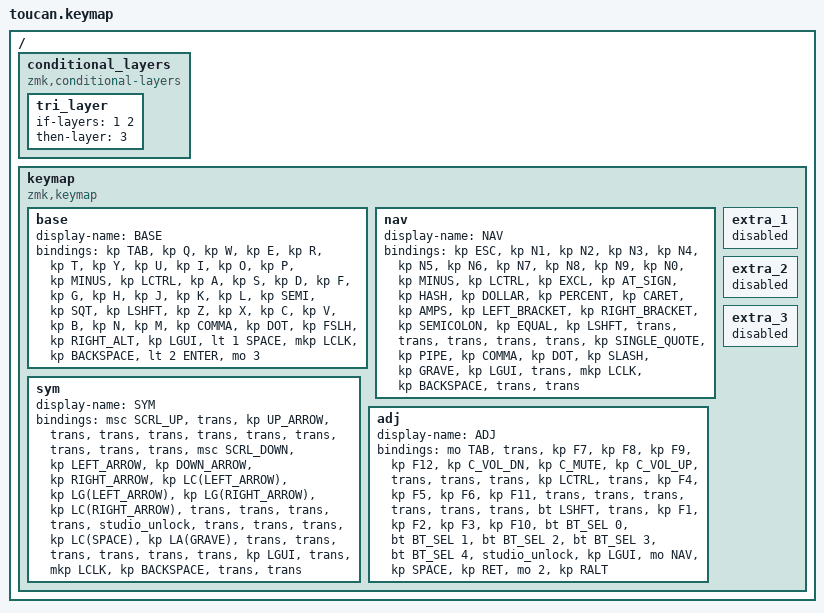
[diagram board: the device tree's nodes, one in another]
#include <behaviors.dtsi>
#include <dt-bindings/zmk/bt.h>
#include <dt-bindings/zmk/keys.h>
#include <dt-bindings/zmk/pointing.h>

#define BASE 0
#define NAV  1
#define SYM  2
#define ADJ  3

/ {
    conditional_layers {
        compatible = "zmk,conditional-layers";

        tri_layer {
            if-layers = <1 2>;
            then-layer = <3>;
        };
    };

    keymap {
        compatible = "zmk,keymap";

        base {
            display-name = "BASE";
            bindings = <
&kp TAB  &kp Q  &kp W  &kp E  &kp R  &kp T  &kp Y  &kp U  &kp I  &kp O  &kp P  &kp MINUS  &kp LCTRL  &kp A  &kp S  &kp D  &kp F  &kp G  &kp H  &kp J  &kp K  &kp L  &kp SEMI  &kp SQT  &kp LSHFT  &kp Z  &kp X  &kp C  &kp V  &kp B  &kp N  &kp M  &kp COMMA  &kp DOT  &kp FSLH  &kp RIGHT_ALT  &kp LGUI  &lt 1 SPACE  &mkp LCLK  &kp BACKSPACE  &lt 2 ENTER  &mo 3
            >;
        };

        nav {
            display-name = "NAV";
            bindings = <
&kp ESC  &kp N1  &kp N2  &kp N3  &kp N4  &kp N5  &kp N6  &kp N7  &kp N8  &kp N9  &kp N0  &kp MINUS  &kp LCTRL  &kp EXCL  &kp AT_SIGN  &kp HASH  &kp DOLLAR  &kp PERCENT  &kp CARET  &kp AMPS  &kp LEFT_BRACKET  &kp RIGHT_BRACKET  &kp SEMICOLON  &kp EQUAL  &kp LSHFT  &trans  &trans  &trans  &trans  &trans  &kp SINGLE_QUOTE  &kp PIPE  &kp COMMA  &kp DOT  &kp SLASH  &kp GRAVE  &kp LGUI  &trans  &mkp LCLK  &kp BACKSPACE  &trans  &trans
            >;
        };

        sym {
            display-name = "SYM";
            bindings = <
&msc SCRL_UP  &trans  &kp UP_ARROW  &trans  &trans  &trans  &trans  &trans  &trans  &trans  &trans  &trans  &msc SCRL_DOWN  &kp LEFT_ARROW  &kp DOWN_ARROW  &kp RIGHT_ARROW  &kp LC(LEFT_ARROW)  &kp LG(LEFT_ARROW)  &kp LG(RIGHT_ARROW)  &kp LC(RIGHT_ARROW)  &trans  &trans  &trans  &trans  &studio_unlock  &trans  &trans  &trans  &kp LC(SPACE)  &kp LA(GRAVE)  &trans  &trans  &trans  &trans  &trans  &trans  &kp LGUI  &trans  &mkp LCLK  &kp BACKSPACE  &trans  &trans
            >;
        };

        adj {
            display-name = "ADJ";
            bindings = <
&mo TAB  &trans  &kp F7  &kp F8  &kp F9  &kp F12  &kp C_VOL_DN  &kp C_MUTE  &kp C_VOL_UP  &trans  &trans  &trans  &kp LCTRL  &trans  &kp F4  &kp F5  &kp F6  &kp F11  &trans  &trans  &trans  &trans  &trans  &trans  &bt LSHFT  &trans  &kp F1  &kp F2  &kp F3  &kp F10  &bt BT_SEL 0  &bt BT_SEL 1  &bt BT_SEL 2  &bt BT_SEL 3  &bt BT_SEL 4  &studio_unlock  &kp LGUI  &mo NAV  &kp SPACE  &kp RET  &mo 2  &kp RALT
            >;
        };

        extra_1 { status = "reserved"; };

        extra_2 { status = "reserved"; };

        extra_3 { status = "reserved"; };
    };
};
